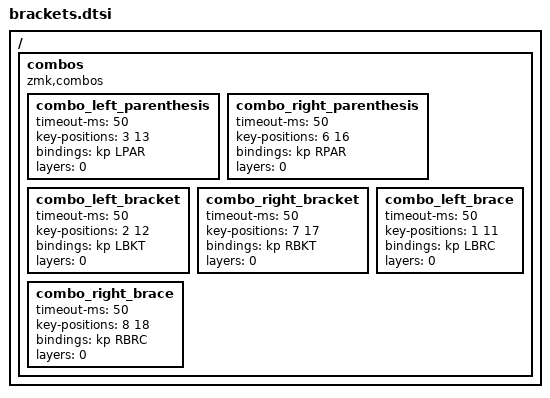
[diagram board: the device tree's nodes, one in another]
/ {
	combos {
		compatible = "zmk,combos";

		combo_left_parenthesis {
			timeout-ms = <50>;
			key-positions = <3 13>;
			bindings = <&kp LPAR>;
			layers = <0>;
		};

        combo_right_parenthesis {
			timeout-ms = <50>;
			key-positions = <6 16>;
			bindings = <&kp RPAR>;
			layers = <0>;
		};

        combo_left_bracket {
			timeout-ms = <50>;
			key-positions = <2 12>;
			bindings = <&kp LBKT>;
			layers = <0>;
		};

        combo_right_bracket {
			timeout-ms = <50>;
			key-positions = <7 17>;
			bindings = <&kp RBKT>;
			layers = <0>;
		};

        combo_left_brace {
			timeout-ms = <50>;
			key-positions = <1 11>;
			bindings = <&kp LBRC>;
			layers = <0>;
		};

        combo_right_brace {
			timeout-ms = <50>;
			key-positions = <8 18>;
			bindings = <&kp RBRC>;
			layers = <0>;
		};
	};
};
